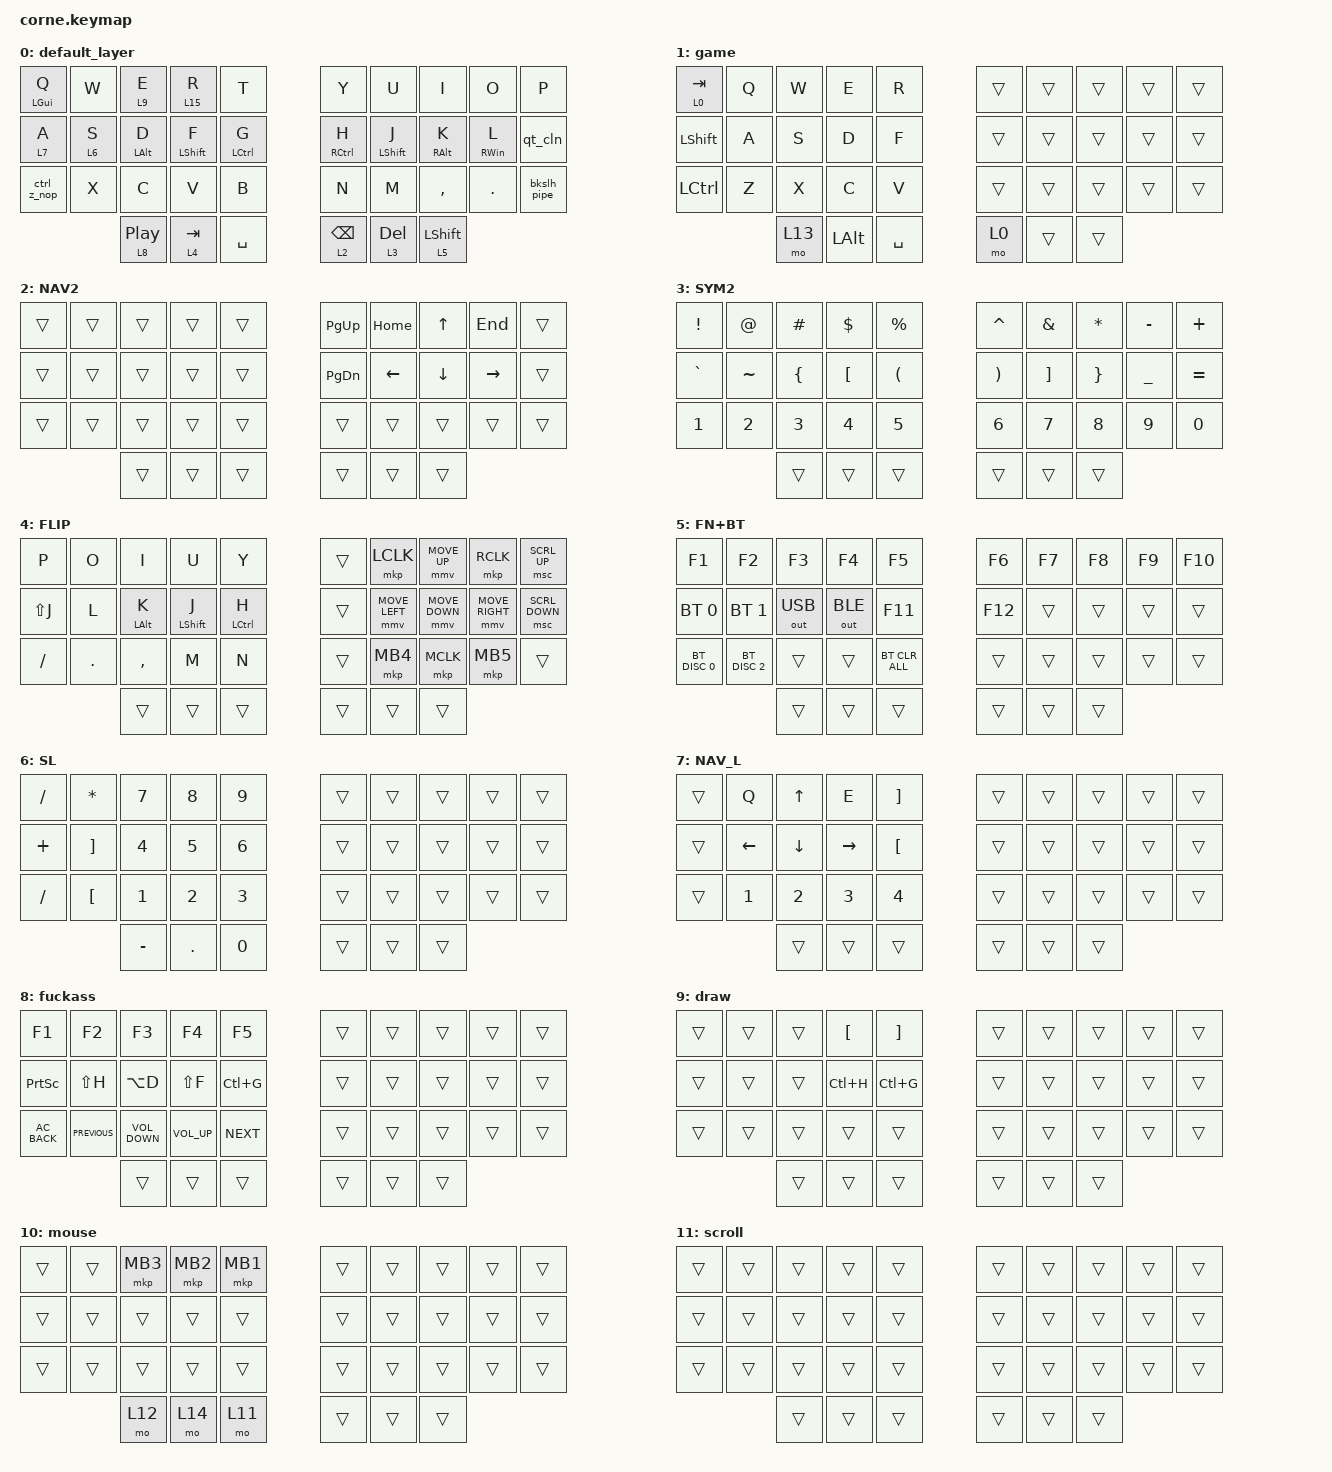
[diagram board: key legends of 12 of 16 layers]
/*
 * Copyright (c) 2020 The ZMK Contributors
 *
 * SPDX-License-Identifier: MIT
 *
 * Shared by the corne_left/corne_right peripherals and the corne_dongle
 * central (ZMK's shield-name fallback strips the _dongle suffix and lands
 * here). Only layer definitions live in this file - the trackball input
 * wiring is central-only and lives in
 * boards/shields/corne/corne_dongle.overlay instead.
 */

#define ZMK_POINTING_DEFAULT_MOVE_VAL 1500

#include <behaviors.dtsi>
#include <dt-bindings/zmk/bt.h>
#include <dt-bindings/zmk/keys.h>
#include <dt-bindings/zmk/outputs.h>
#include <dt-bindings/zmk/pointing.h>

&mt {
    flavor = "balanced";
    hold-while-undecided;
};

/ {
    chosen { zmk,matrix_transform = &five_column_transform; };

    combos {
        compatible = "zmk,combos";

        enter {
            bindings = <&kp ENTER>;
            key-positions = <16 17>;
        };

        to_game {
            bindings = <&to 1>;
            key-positions = <4 0>;
            layers = <0>;
        };

        enter_L {
            bindings = <&kp ENTER>;
            key-positions = <12 13>;
            layers = <0 7 3 4>;
        };

        backspace_l {
            bindings = <&kp BACKSPACE>;
            key-positions = <2 3>;
            require-prior-idle-ms = <250>;
        };

        l_esc {
            bindings = <&kp ESCAPE>;
            key-positions = <2 1>;
            layers = <0 1>;
        };

        l_menu {
            bindings = <&kp K_CONTEXT_MENU>;
            key-positions = <23 24>;
            layers = <0>;
        };

        r_ins {
            bindings = <&kp INSERT>;
            key-positions = <5 6>;
            layers = <0>;
        };

        num_plus {
            bindings = <&kp PLUS>;
            key-positions = <4 3>;
            layers = <6>;
        };

        num_div {
            bindings = <&kp SLASH>;
            key-positions = <14 13>;
            layers = <6>;
        };

        l_delete {
            bindings = <&kp DELETE>;
            key-positions = <23 22>;
            layers = <0>;
        };

        l_caps {
            bindings = <&kp CAPS>;
            key-positions = <10 11>;
            layers = <0>;
            timeout-ms = <40>;
            require-prior-idle-ms = <250>;
        };

        l_capsw {
            bindings = <&sticky_shift LEFT_SHIFT>;
            key-positions = <20 21>;
            timeout-ms = <40>;
            layers = <0>;
            require-prior-idle-ms = <250>;
        };

        r_click {
            bindings = <&kp C_AC_FORWARD>;
            key-positions = <4 3>;
        };

        l_click {
            bindings = <&kp LC(Z)>;
            key-positions = <3 14>;
            layers = <0>;
        };

        l_back {
            bindings = <&kp C_AC_BACK>;
            key-positions = <0 1>;
        };

        nogaming {
            bindings = <&to 0>;
            key-positions = <0 4>;
            layers = <1>;
        };

        ctrl_shift {
            bindings = <&kp LC(LEFT_SHIFT)>;
            key-positions = <13 14>;
            layers = <0>;
        };
    };

    behaviors {
        td_screen: td_screen {
            compatible = "zmk,behavior-tap-dance";
            label = "TD_SCREEN";
            #binding-cells = <0>;
            bindings = <&kp C_MENU>, <&kp PRINTSCREEN>;
        };

        qt_cln: qt_cln {
            compatible = "zmk,behavior-mod-morph";
            label = "QT_CLN";
            bindings = <&kp SQT>, <&kp SEMICOLON>;

            #binding-cells = <0>;
            mods = <(MOD_RCTL|MOD_LCTL)>;
        };

        bkslh_pipe: bkslh_pipe {
            compatible = "zmk,behavior-mod-morph";
            label = "BKSLH_PIPE";
            bindings = <&kp SLASH>, <&kp BACKSLASH>;

            #binding-cells = <0>;
            mods = <(MOD_RCTL|MOD_LCTL)>;
        };

        alt_holdtap: alt_holdtap {
            compatible = "zmk,behavior-hold-tap";
            label = "ALT_HOLDTAP";
            bindings = <&kp>, <&kp>;

            #binding-cells = <2>;
            tapping-term-ms = <200>;
            flavor = "tap-preferred";
        };

        nbmr_wrd: nbmr_wrd {
            compatible = "zmk,behavior-caps-word";
            label = "NBMR_WRD";
            #binding-cells = <0>;
            continue-list = <NUMBER_0 NUMBER_9 NUMBER_8 NUMBER_7 NUMBER_4 NUMBER_5 NUMBER_6 NUMBER_1 NUMBER_2 NUMBER_3 MINUS PLUS SLASH ASTERISK DOT>;
        };

        nmbr_tap: nmbr_tap {
            compatible = "zmk,behavior-hold-tap";
            label = "NMBR_TAP";
            bindings = <&mo>, <&nmbr_toggle>;

            #binding-cells = <2>;
            tapping-term-ms = <200>;
            flavor = "tap-preferred";
        };

        tap_hold_key: tap_hold_key {
            compatible = "zmk,behavior-hold-tap";
            label = "TAP_HOLD_KEY";
            bindings = <&kp>, <&mkp>;

            #binding-cells = <2>;
            tapping-term-ms = <200>;
            flavor = "tap-preferred";
        };

        urob_hrm: urob_hrm {
            compatible = "zmk,behavior-hold-tap";
            label = "UROB_HRM";
            bindings = <&kp>, <&kp>;

            #binding-cells = <2>;
            tapping-term-ms = <220>;
            quick-tap-ms = <175>;
            hold-trigger-on-release;
            flavor = "balanced";
            hold-while-undecided;
        };

        spc_flip: spc_flip {
            compatible = "zmk,behavior-hold-tap";
            label = "SPC_FLIP";
            bindings = <&mo>, <&kp>;

            #binding-cells = <2>;
            tapping-term-ms = <180>;
            flavor = "tap-preferred";
        };

        hold_sticky: hold_sticky {
            compatible = "zmk,behavior-hold-tap";
            label = "HOLD_STICKY";
            bindings = <&mo>, <&sticky_shift>;

            #binding-cells = <2>;
            tapping-term-ms = <120>;
            flavor = "balanced";
        };

        sticky_shift: sticky_shift {
            compatible = "zmk,behavior-sticky-key";
            label = "STICKY_SHIFT";
            bindings = <&kp>;
            #binding-cells = <1>;
            release-after-ms = <500>;
            quick-release;
            ignore-modifiers;
        };

        ctrl_z_nop: ctrl_z_nop {
            compatible = "zmk,behavior-mod-morph";
            label = "CTRL_Z_NOP";
            bindings = <&kp Z>, <&none>;

            #binding-cells = <0>;
            mods = <(MOD_LCTL|MOD_RCTL)>;
        };
    };

    macros {
        nmbr_toggle: nmbr_toggle {
            compatible = "zmk,behavior-macro";
            #binding-cells = <0>;
            bindings =
                <&macro_tap_time 1000>,
                <&tog 6>,
                <&macro_release>,
                <&tog 6>;

            label = "NMBR_TOGGLE";
        };

        sx0: sx0 {
            compatible = "zmk,behavior-macro";
            #binding-cells = <0>;
            bindings = <&kp S &kp X &kp N0 &kp RET>;
            label = "SX0";
        };

        sy0: sy0 {
            compatible = "zmk,behavior-macro";
            #binding-cells = <0>;
            bindings = <&kp S &kp Y &kp N0 &kp RET>;
            label = "SY0";
        };
    };

    keymap {
        compatible = "zmk,keymap";

        default_layer {
            // -----------------------------------------------------------------------------------------
            // |  TAB |  Q  |  W  |  E  |  R  |  T  |   |  Y  |  U   |  I  |  O  |  P  | BKSP |
            // | CTRL |  A  |  S  |  D  |  F  |  G  |   |  H  |  J   |  K  |  L  |  ;  |  '   |
            // | SHFT |  Z  |  X  |  C  |  V  |  B  |   |  N  |  M   |  ,  |  .  |  /  | ESC  |
            //                    | GUI | LWR | SPC |   | ENT | RSE  | ALT |

            bindings = <
&alt_holdtap LEFT_GUI Q  &kp W      &lt 9 E                  &lt 15 R                &kp T              &kp Y                      &kp U        &kp I                     &kp O                     &kp P
&lt 7 A                  &lt 6 S    &alt_holdtap LEFT_ALT D  &urob_hrm LEFT_SHIFT F  &urob_hrm LCTRL G  &mt RCTRL H                &mt LSHFT J  &alt_holdtap RIGHT_ALT K  &alt_holdtap RIGHT_WIN L  &qt_cln
&ctrl_z_nop              &kp X      &kp C                    &kp V                   &kp B              &kp N                      &kp M        &kp COMMA                 &kp PERIOD                &bkslh_pipe
&lt 8 C_PP               &lt 4 TAB  &kp SPACE                &lt 2 BACKSPACE         &lt 3 DELETE       &hold_sticky 5 LEFT_SHIFT
            >;
        };

        game {
            bindings = <
&lt 0 TAB       &kp Q         &kp W      &kp E  &kp R   &trans  &trans  &trans  &trans  &trans
&kp LEFT_SHIFT  &kp A         &kp S      &kp D  &kp F   &trans  &trans  &trans  &trans  &trans
&kp LCTRL       &kp Z         &kp X      &kp C  &kp V   &trans  &trans  &trans  &trans  &trans
&mo 13          &kp LEFT_ALT  &kp SPACE  &mo 0  &trans  &trans
            >;
        };

        NAV2 {
            bindings = <
&trans  &trans  &trans  &trans  &trans  &kp PAGE_UP  &kp HOME  &kp UP    &kp END    &trans
&trans  &trans  &trans  &trans  &trans  &kp PG_DN    &kp LEFT  &kp DOWN  &kp RIGHT  &trans
&trans  &trans  &trans  &trans  &trans  &trans       &trans    &trans    &trans     &trans
&trans  &trans  &trans  &trans  &trans  &trans
            >;
        };

        SYM2 {
            bindings = <
&kp EXCLAMATION  &kp AT_SIGN  &kp HASH        &kp DOLLAR  &kp PERCENT           &kp CARET              &kp AMPERSAND  &kp ASTERISK     &kp MINUS       &kp PLUS
&kp GRAVE        &kp TILDE    &kp LEFT_BRACE  &kp LBKT    &kp LEFT_PARENTHESIS  &kp RIGHT_PARENTHESIS  &kp RBKT       &kp RIGHT_BRACE  &kp UNDERSCORE  &kp EQUAL
&kp N1           &kp N2       &kp N3          &kp N4      &kp N5                &kp N6                 &kp N7         &kp N8           &kp N9          &kp N0
&trans           &trans       &trans          &trans      &trans                &trans
            >;
        };

        FLIP {
            bindings = <
&kp P      &kp O       &kp I           &kp U             &kp Y        &trans  &mkp LCLK       &mmv MOVE_UP    &mkp RCLK        &msc SCRL_UP
&kp LS(J)  &kp L       &mt LEFT_ALT K  &mt LEFT_SHIFT J  &mt LCTRL H  &trans  &mmv MOVE_LEFT  &mmv MOVE_DOWN  &mmv MOVE_RIGHT  &msc SCRL_DOWN
&kp SLASH  &kp PERIOD  &kp COMMA       &kp M             &kp N        &trans  &mkp MB4        &mkp MCLK       &mkp MB5         &trans
&trans     &trans      &trans          &trans            &trans       &trans
            >;
        };

        FN+BT {
            bindings = <
&kp F1         &kp F2         &kp F3        &kp F4        &kp F5          &kp F6   &kp F7  &kp F8  &kp F9  &kp F10
&bt BT_SEL 0   &bt BT_SEL 1   &out OUT_USB  &out OUT_BLE  &kp F11         &kp F12  &trans  &trans  &trans  &trans
&bt BT_DISC 0  &bt BT_DISC 2  &trans        &trans        &bt BT_CLR_ALL  &trans   &trans  &trans  &trans  &trans
&trans         &trans         &trans        &trans        &trans          &trans
            >;
        };

        NUM {
            bindings = <
&kp SLASH  &kp ASTERISK       &kp N7  &kp N8  &kp N9  &trans  &trans  &trans  &trans  &trans
&kp PLUS   &kp RIGHT_BRACKET  &kp N4  &kp N5  &kp N6  &trans  &trans  &trans  &trans  &trans
&kp SLASH  &kp LEFT_BRACKET   &kp N1  &kp N2  &kp N3  &trans  &trans  &trans  &trans  &trans
&kp MINUS  &kp PERIOD         &kp N0  &trans  &trans  &trans
            >;

            label = "SL";
        };

        NAV_L {
            bindings = <
&trans  &kp Q         &kp UP    &kp E      &kp RIGHT_BRACKET  &trans  &trans  &trans  &trans  &trans
&trans  &kp LEFT      &kp DOWN  &kp RIGHT  &kp LEFT_BRACKET   &trans  &trans  &trans  &trans  &trans
&trans  &kp NUMBER_1  &kp N2    &kp N3     &kp N4             &trans  &trans  &trans  &trans  &trans
&trans  &trans        &trans    &trans     &trans             &trans
            >;
        };

        fuckass {
            bindings = <
&kp F1           &kp F2          &kp F3             &kp F4           &kp F5      &trans  &trans  &trans  &trans  &trans
&kp PRINTSCREEN  &kp LS(H)       &kp LA(D)          &kp LS(F)        &kp LC(G)   &trans  &trans  &trans  &trans  &trans
&kp C_AC_BACK    &kp C_PREVIOUS  &kp C_VOLUME_DOWN  &kp C_VOLUME_UP  &kp C_NEXT  &trans  &trans  &trans  &trans  &trans
&trans           &trans          &trans             &trans           &trans      &trans
            >;
        };

        draw {
            bindings = <
&trans  &trans  &trans  &kp LEFT_BRACKET  &kp RIGHT_BRACKET  &trans  &trans  &trans  &trans  &trans
&trans  &trans  &trans  &kp LC(H)         &kp LC(G)          &trans  &trans  &trans  &trans  &trans
&trans  &trans  &trans  &trans            &trans             &trans  &trans  &trans  &trans  &trans
&trans  &trans  &trans  &trans            &trans             &trans
            >;
        };

        mouse {
            // Auto-activated by trackball movement (see &trackball_listener
            // in boards/shields/corne/corne_dongle.overlay). Holding the
            // C_PP thumb key (position 30) switches the trackball to volume
            // mode (layer 12), holding SPACE (position 32) switches it to
            // scroll mode (layer 11), and holding TAB (position 31)
            // switches it to zippy mode (layer 14, full speed - default
            // movement is precise, half speed).

            bindings = <
&trans  &trans  &mkp MB3  &mkp MB2  &mkp MB1  &trans  &trans  &trans  &trans  &trans
&trans  &trans  &trans    &trans    &trans    &trans  &trans  &trans  &trans  &trans
&trans  &trans  &trans    &trans    &trans    &trans  &trans  &trans  &trans  &trans
&mo 12  &mo 14  &mo 11    &trans    &trans    &trans
            >;
        };

        scroll {
            // Momentary layer only used as a gate for &trackball_listener's
            // scroll_layer override - deliberately transparent otherwise.

            bindings = <
&trans  &trans  &trans  &trans  &trans  &trans  &trans  &trans  &trans  &trans
&trans  &trans  &trans  &trans  &trans  &trans  &trans  &trans  &trans  &trans
&trans  &trans  &trans  &trans  &trans  &trans  &trans  &trans  &trans  &trans
&trans  &trans  &trans  &trans  &trans  &trans
            >;
        };

        volume {
            // Momentary layer only used as a gate for &trackball_listener's
            // volume_layer override - deliberately transparent otherwise.

            bindings = <
&trans  &trans  &trans  &trans  &trans  &trans  &trans  &trans  &trans  &trans
&trans  &trans  &trans  &trans  &trans  &trans  &trans  &trans  &trans  &trans
&trans  &trans  &trans  &trans  &trans  &trans  &trans  &trans  &trans  &trans
&trans  &trans  &trans  &trans  &trans  &trans
            >;
        };

        game_up {
            bindings = <
&trans  &kp NUMBER_1  &kp N2  &kp N3  &kp N4  &trans  &trans  &trans  &trans  &trans
&trans  &trans        &trans  &trans  &trans  &trans  &trans  &trans  &trans  &trans
&trans  &trans        &trans  &trans  &trans  &trans  &trans  &trans  &trans  &trans
&trans  &trans        &trans  &trans  &trans  &trans
            >;
        };

        zippy {
            // Momentary layer only used as a gate for &trackball_listener's
            // zippy_layer override - deliberately transparent otherwise.
            // Kept LAST on purpose: everything above keeps its index, and
            // the listener in boards/shields/corne/corne_dongle.overlay
            // hardcodes these layer numbers.

            bindings = <
&trans  &trans  &trans  &trans  &trans  &trans  &trans  &trans  &trans  &trans
&trans  &trans  &trans  &trans  &trans  &trans  &trans  &trans  &trans  &trans
&trans  &trans  &trans  &trans  &trans  &trans  &trans  &trans  &trans  &trans
&trans  &trans  &trans  &trans  &trans  &trans
            >;
        };

        ctrlz {
            bindings = <
&kp LC(Y)  &kp LS(LC(Z))  &kp LC(Z)  &trans  &trans  &trans  &trans  &trans  &trans  &trans
&trans     &sx0           &sy0       &trans  &trans  &trans  &trans  &trans  &trans  &trans
&trans     &trans         &trans     &trans  &trans  &trans  &trans  &trans  &trans  &trans
&trans     &trans         &trans     &trans  &trans  &trans
            >;
        };
    };
};
